# MSP432E401Y register map
Vendor: Texas Instruments; File version: 3.200
CPU: CM4 r1p2, little endian, no MPU, no FPU, 0x3 interrupt priority bits, 0x0 interrupts
Registers are 32-bit, read-write, no defined reset value unless marked. A register's access mark holds for its fields unless they carry their own. Offsets are from the block's base; [hi:lo] are bit positions; {n}, {i} and the like mark numbered series.

## HIB — Register map for HIB peripheral
Base 0x400FC000; register names take the prefix HIB
0x00 RTCC — Hibernation RTC Counter
  [31:0] HIB_RTCC — RTC Counter
0x04 RTCM0 — Hibernation RTC Match 0
  [31:0] HIB_RTCM0 — RTC Match 0
0x0C RTCLD — Hibernation RTC Load
  [31:0] HIB_RTCLD — RTC Load
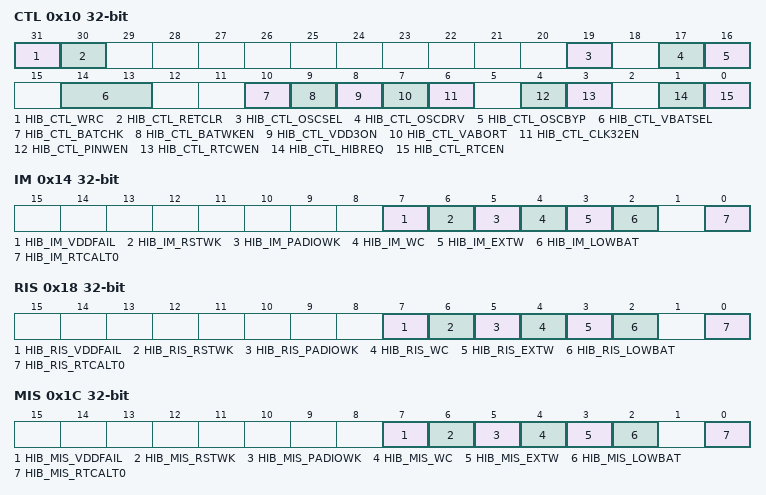
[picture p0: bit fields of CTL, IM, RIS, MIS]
0x10 CTL — Hibernation Control
  [31] HIB_CTL_WRC — Write Complete/Capable
  [30] HIB_CTL_RETCLR — GPIO Retention/Clear
  [19] HIB_CTL_OSCSEL — Oscillator Select
  [17] HIB_CTL_OSCDRV — Oscillator Drive Capability
  [16] HIB_CTL_OSCBYP — Oscillator Bypass
  [14:13] HIB_CTL_VBATSEL — Select for Low-Battery Comparator
    0=HIB_CTL_VBATSEL_1_9V (1.9 Volts); 1=HIB_CTL_VBATSEL_2_1V (2.1 Volts (default)); 2=HIB_CTL_VBATSEL_2_3V (2.3 Volts); 3=HIB_CTL_VBATSEL_2_5V (2.5 Volts)
  [10] HIB_CTL_BATCHK — Check Battery Status
  [9] HIB_CTL_BATWKEN — Wake on Low Battery
  [8] HIB_CTL_VDD3ON — VDD Powered
  [7] HIB_CTL_VABORT — Power Cut Abort Enable
  [6] HIB_CTL_CLK32EN — Clocking Enable
  [4] HIB_CTL_PINWEN — External Wake Pin Enable
  [3] HIB_CTL_RTCWEN — RTC Wake-up Enable
  [1] HIB_CTL_HIBREQ — Hibernation Request
  [0] HIB_CTL_RTCEN — RTC Timer Enable
0x14 IM — Hibernation Interrupt Mask
  [7] HIB_IM_VDDFAIL — VDD Fail Interrupt Mask
  [6] HIB_IM_RSTWK — Reset Pad I/O Wake-Up Interrupt Mask
  [5] HIB_IM_PADIOWK — Pad I/O Wake-Up Interrupt Mask
  [4] HIB_IM_WC — External Write Complete/Capable Interrupt Mask
  [3] HIB_IM_EXTW — External Wake-Up Interrupt Mask
  [2] HIB_IM_LOWBAT — Low Battery Voltage Interrupt Mask
  [0] HIB_IM_RTCALT0 — RTC Alert 0 Interrupt Mask
0x18 RIS — Hibernation Raw Interrupt Status
  [7] HIB_RIS_VDDFAIL — VDD Fail Raw Interrupt Status
  [6] HIB_RIS_RSTWK — Reset Pad I/O Wake-Up Raw Interrupt Status
  [5] HIB_RIS_PADIOWK — Pad I/O Wake-Up Raw Interrupt Status
  [4] HIB_RIS_WC — Write Complete/Capable Raw Interrupt Status
  [3] HIB_RIS_EXTW — External Wake-Up Raw Interrupt Status
  [2] HIB_RIS_LOWBAT — Low Battery Voltage Raw Interrupt Status
  [0] HIB_RIS_RTCALT0 — RTC Alert 0 Raw Interrupt Status
0x1C MIS — Hibernation Masked Interrupt Status
  [7] HIB_MIS_VDDFAIL — VDD Fail Interrupt Mask
  [6] HIB_MIS_RSTWK — Reset Pad I/O Wake-Up Interrupt Mask
  [5] HIB_MIS_PADIOWK — Pad I/O Wake-Up Interrupt Mask
  [4] HIB_MIS_WC — Write Complete/Capable Masked Interrupt Status
  [3] HIB_MIS_EXTW — External Wake-Up Masked Interrupt Status
  [2] HIB_MIS_LOWBAT — Low Battery Voltage Masked Interrupt Status
  [0] HIB_MIS_RTCALT0 — RTC Alert 0 Masked Interrupt Status
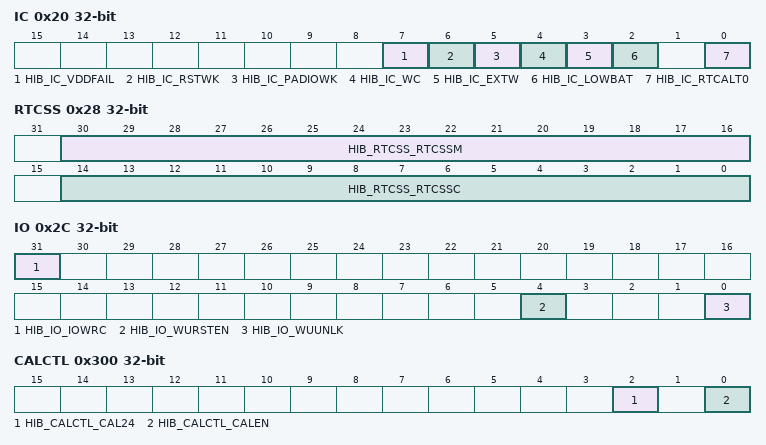
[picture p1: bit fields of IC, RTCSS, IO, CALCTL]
0x20 IC — Hibernation Interrupt Clear
  [7] HIB_IC_VDDFAIL — VDD Fail Interrupt Clear
  [6] HIB_IC_RSTWK — Reset Pad I/O Wake-Up Interrupt Clear
  [5] HIB_IC_PADIOWK — Pad I/O Wake-Up Interrupt Clear
  [4] HIB_IC_WC — Write Complete/Capable Interrupt Clear
  [3] HIB_IC_EXTW — External Wake-Up Interrupt Clear
  [2] HIB_IC_LOWBAT — Low Battery Voltage Interrupt Clear
  [0] HIB_IC_RTCALT0 — RTC Alert0 Masked Interrupt Clear
0x24 RTCT — Hibernation RTC Trim
  [15:0] HIB_RTCT_TRIM — RTC Trim Value
0x28 RTCSS — Hibernation RTC Sub Seconds
  [30:16] HIB_RTCSS_RTCSSM — RTC Sub Seconds Match
  [14:0] HIB_RTCSS_RTCSSC — RTC Sub Seconds Count
0x2C IO — Hibernation IO Configuration
  [31] HIB_IO_IOWRC — I/O Write Complete
  [4] HIB_IO_WURSTEN — Reset Wake Source Enable
  [0] HIB_IO_WUUNLK — I/O Wake Pad Configuration Enable
0x30 DATA — Hibernation Data
  [31:0] HIB_DATA_RTD — Hibernation Module NV Data
0x300 CALCTL — Hibernation Calendar Control
  [2] HIB_CALCTL_CAL24 — Calendar Mode
  [0] HIB_CALCTL_CALEN — RTC Calendar/Counter Mode Select
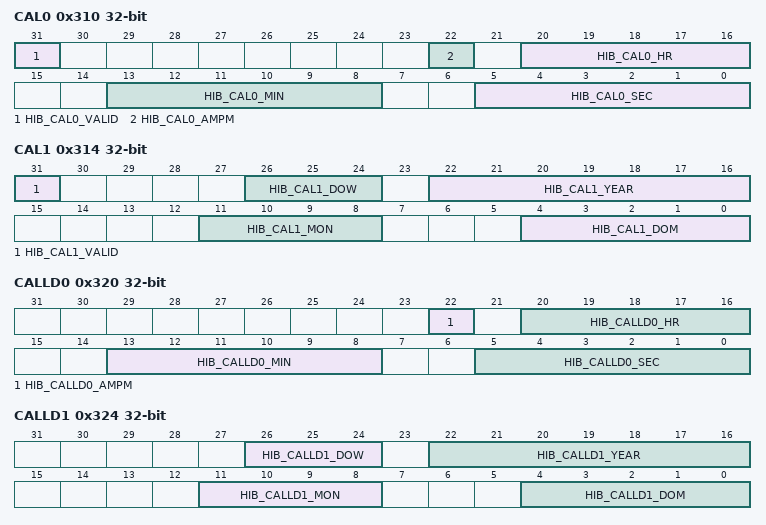
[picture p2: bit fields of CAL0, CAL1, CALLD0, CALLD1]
0x310 CAL0 — Hibernation Calendar 0
  [31] HIB_CAL0_VALID — Valid Calendar Load
  [22] HIB_CAL0_AMPM — AM/PM Designation
  [20:16] HIB_CAL0_HR — Hours
  [13:8] HIB_CAL0_MIN — Minutes
  [5:0] HIB_CAL0_SEC — Seconds
0x314 CAL1 — Hibernation Calendar 1
  [31] HIB_CAL1_VALID — Valid Calendar Load
  [26:24] HIB_CAL1_DOW — Day of Week
  [22:16] HIB_CAL1_YEAR — Year Value
  [11:8] HIB_CAL1_MON — Month
  [4:0] HIB_CAL1_DOM — Day of Month
0x320 CALLD0 wo — Hibernation Calendar Load 0
  [22] HIB_CALLD0_AMPM — AM/PM Designation
  [20:16] HIB_CALLD0_HR — Hours
  [13:8] HIB_CALLD0_MIN — Minutes
  [5:0] HIB_CALLD0_SEC — Seconds
0x324 CALLD1 wo — Hibernation Calendar Load
  [26:24] HIB_CALLD1_DOW — Day of Week
  [22:16] HIB_CALLD1_YEAR — Year Value
  [11:8] HIB_CALLD1_MON — Month
  [4:0] HIB_CALLD1_DOM — Day of Month
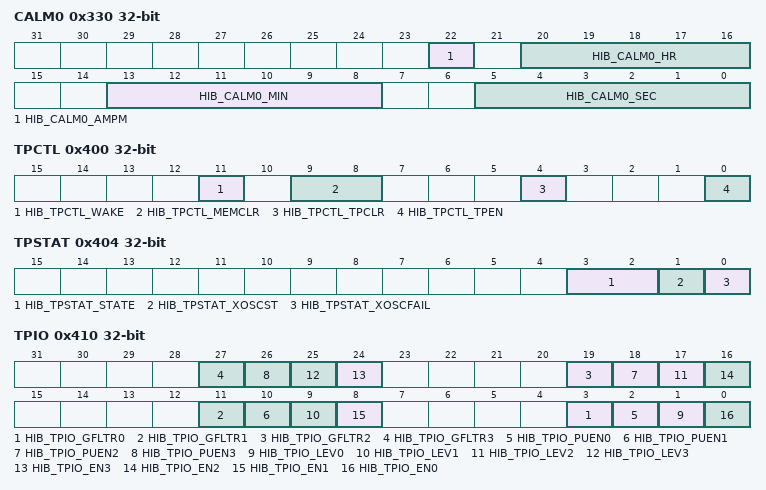
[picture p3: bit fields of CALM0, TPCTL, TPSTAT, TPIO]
0x330 CALM0 — Hibernation Calendar Match 0
  [22] HIB_CALM0_AMPM — AM/PM Designation
  [20:16] HIB_CALM0_HR — Hours
  [13:8] HIB_CALM0_MIN — Minutes
  [5:0] HIB_CALM0_SEC — Seconds
0x334 CALM1 — Hibernation Calendar Match 1
  [4:0] HIB_CALM1_DOM — Day of Month
0x360 LOCK — Hibernation Lock
  [31:0] HIB_LOCK_HIBLOCK — HIbernate Lock
0x400 TPCTL — HIB Tamper Control
  [11] HIB_TPCTL_WAKE — Wake from Hibernate on a Tamper Event
  [9:8] HIB_TPCTL_MEMCLR — HIB Memory Clear on Tamper Event
    0=HIB_TPCTL_MEMCLR_NONE (Do not Clear HIB memory on tamper event); 1=HIB_TPCTL_MEMCLR_LOW32 (Clear Lower 32 Bytes of HIB memory on tamper event); 2=HIB_TPCTL_MEMCLR_HIGH32 (Clear upper 32 Bytes of HIB memory on tamper event); 3=HIB_TPCTL_MEMCLR_ALL (Clear all HIB memory on tamper event)
  [4] HIB_TPCTL_TPCLR — Tamper Event Clear
  [0] HIB_TPCTL_TPEN — Tamper Module Enable
0x404 TPSTAT — HIB Tamper Status
  [3:2] HIB_TPSTAT_STATE — Tamper Module Status
    0=HIB_TPSTAT_STATE_DISABLED (Tamper disabled); 1=HIB_TPSTAT_STATE_CONFIGED (Tamper configured); 2=HIB_TPSTAT_STATE_ERROR (Tamper pin event occurred)
  [1] HIB_TPSTAT_XOSCST — External Oscillator Status
  [0] HIB_TPSTAT_XOSCFAIL — External Oscillator Failure
0x410 TPIO — HIB Tamper I/O Control
  [8n+3] HIB_TPIO_GFLTR{n} (n=0..3) — TMPR{n} Glitch Filtering
  [8n+2] HIB_TPIO_PUEN{n} (n=0..3) — TMPR{n} Internal Weak Pull-up Enable
  [8n+1] HIB_TPIO_LEV{n} (n=0..3) — TMPR{n} Trigger Level
  [24] HIB_TPIO_EN3 — TMPR3 Enable
  [16] HIB_TPIO_EN2 — TMPR2 Enable
  [8] HIB_TPIO_EN1 — TMPR1Enable
  [0] HIB_TPIO_EN0 — TMPR0 Enable
0x4E0 TPLOG0 — HIB Tamper Log 0
  [31:0] HIB_TPLOG0_TIME — Tamper Log Calendar Information
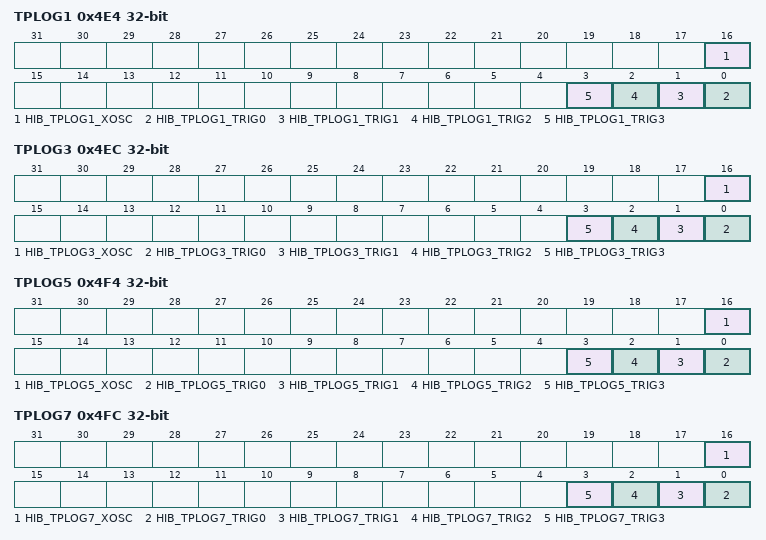
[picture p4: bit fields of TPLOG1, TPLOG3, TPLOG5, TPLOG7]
0x4E4 TPLOG1 — HIB Tamper Log 1
  [16] HIB_TPLOG1_XOSC — Status of external 32
  [n] HIB_TPLOG1_TRIG{n} (n=0..3) — Status of TMPR[{n}] Trigger
0x4E8 TPLOG2 — HIB Tamper Log 2
  [31:0] HIB_TPLOG2_TIME — Tamper Log Calendar Information
0x4EC TPLOG3 — HIB Tamper Log 3
  [16] HIB_TPLOG3_XOSC — Status of external 32
  [n] HIB_TPLOG3_TRIG{n} (n=0..3) — Status of TMPR[{n}] Trigger
0x4F0 TPLOG4 — HIB Tamper Log 4
  [31:0] HIB_TPLOG4_TIME — Tamper Log Calendar Information
0x4F4 TPLOG5 — HIB Tamper Log 5
  [16] HIB_TPLOG5_XOSC — Status of external 32
  [n] HIB_TPLOG5_TRIG{n} (n=0..3) — Status of TMPR[{n}] Trigger
0x4F8 TPLOG6 — HIB Tamper Log 6
  [31:0] HIB_TPLOG6_TIME — Tamper Log Calendar Information
0x4FC TPLOG7 — HIB Tamper Log 7
  [16] HIB_TPLOG7_XOSC — Status of external 32
  [n] HIB_TPLOG7_TRIG{n} (n=0..3) — Status of TMPR[{n}] Trigger
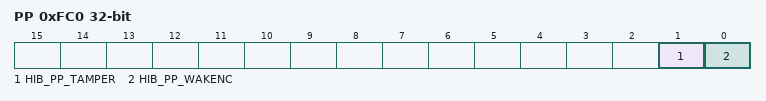
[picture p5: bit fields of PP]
0xFC0 PP — Hibernation Peripheral Properties
  [1] HIB_PP_TAMPER — Tamper Pin Presence
  [0] HIB_PP_WAKENC — Wake Pin Presence
0xFC8 CC — Hibernation Clock Control
  [0] HIB_CC_SYSCLKEN — RTCOSC to System Clock Enable
